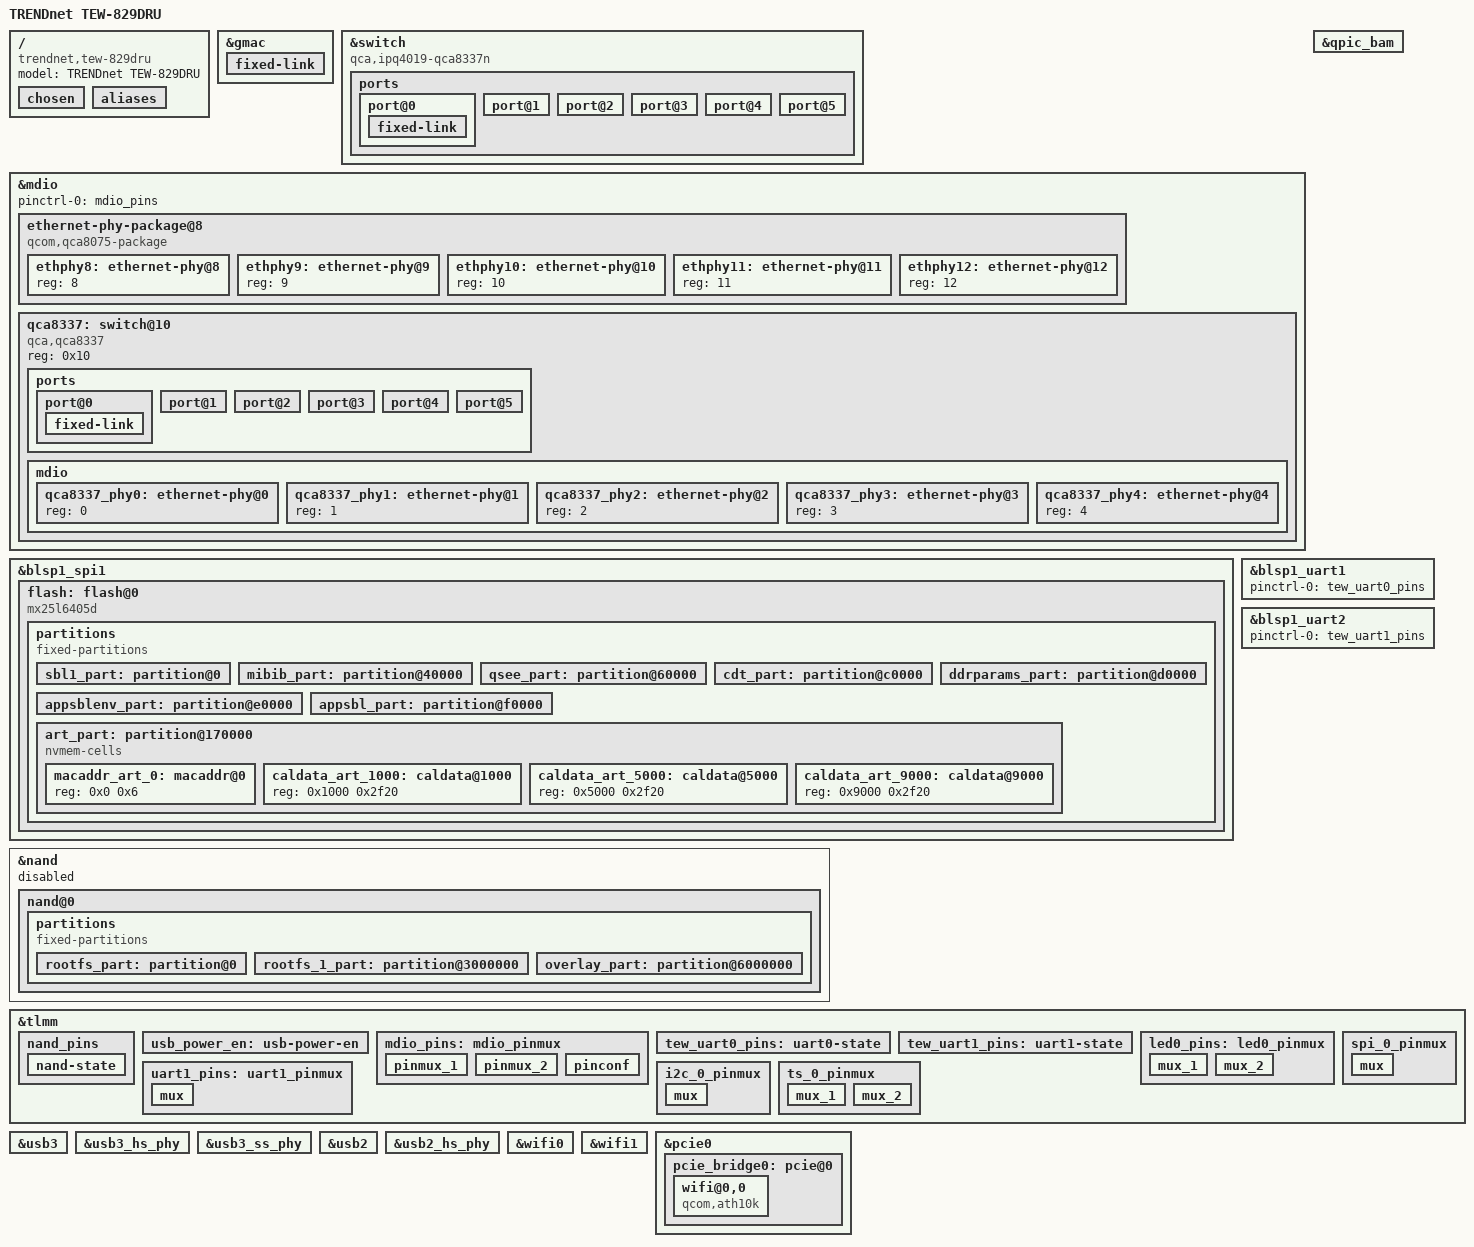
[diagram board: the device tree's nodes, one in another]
// SPDX-License-Identifier: GPL-2.0
// Copyright (c) 2018, The Linux Foundation. All rights reserved.
// Copyright (c) 2026, Your Name <your@email.com>

/*
 *		What is working?
 *
 *			- CPU
 *			- RAM
 *			- 8MB Flash (Macronix MX25L6433F SPI NOR 8MB // dual bootloader, ART, etc.)
 *			- UART
 *			- USB
  *			- wifi (QCA9984, QCA4019)
 *
 *		What is NOT working?
 *
 *			- 128MB nand (Micron MT29F1G08ABADA NAND 128MB // 2x kernel, 2x rootfs, 1x rootfs_data)
 *			- switches (QCA8075, QCA8335)
 *
 *	WARNING: ENSURE BOARD.BIN AND CALDATA IS NOT COMMITTED TO GIT REPOSITORY (INTELLECTUAL PROPERTY CONCERNS)
 *
 */

#include "qcom-ipq4019-ap.dk04.1.dtsi"

/ {

	model = "TRENDnet TEW-829DRU";
	compatible = "trendnet,tew-829dru", "qcom,ipq4019-dk04.1-c1", "qcom,ipq4019";
	
	chosen {
		bootargs = "console=ttyMSM0,115200n8 rootfstype=squashfs,jffs2 iommu.passthrough=1";
	};
	
	aliases {
		mtd0 = &sbl1_part;
		mtd1 = &mibib_part;
		mtd2 = &qsee_part;
		mtd3 = &cdt_part;
		mtd4 = &ddrparams_part;
		mtd5 = &appsblenv_part;
		mtd6 = &appsbl_part;
		mtd7 = &art_part;
		mtd8 = &rootfs_part;
		mtd9 = &rootfs_1_part;
		mtd10 = &overlay_part;
	};
}; /* end of root block */

/* EDMA — the CPU-facing ethernet, both switches connect here */
&gmac {
    status = "okay";
    phy-mode = "internal";
	/* dual-GMAC: RRD port-id 5 = GMAC1 = QCA8337 switch */
    qcom,gmac1-port = <5>;
    fixed-link {
        speed = <1000>;
        full-duplex;
        pause;
    };
}; /* end of gmac */

/* TOP SWITCH: ESS built-in (QCA8075 via PSGMII) at c000000 */
/* compatible MUST be qca,ipq4019-qca8337n — this is what ran on the device */
&switch {
    status = "okay";
    compatible = "qca,ipq4019-qca8337n";

    mdio-bus = <&mdio>;
    psgmii-ethphy = <&ethphy12>;  /* reg=0x0c, the cal PHY at base+4 */

    /delete-node/ ports;

    ports {
        #address-cells = <1>;
        #size-cells = <0>;

        port@0 {
            reg = <0>;
            label = "cpu";
            ethernet = <&gmac>;
            phy-mode = "internal";
            fixed-link {
                speed = <1000>;
                full-duplex;
                pause;
                asym-pause;
            };
        };

        port@1 {
            reg = <1>;
            label = "wan1";
            phy-handle = <&ethphy8>;
            phy-mode = "psgmii";
            status = "okay";
        };

        port@2 {
            reg = <2>;
            label = "wan2";
            phy-handle = <&ethphy9>;
            phy-mode = "psgmii";
            status = "okay";
        };

        port@3 {
            reg = <3>;
            label = "lan1";
            phy-handle = <&ethphy10>;
            phy-mode = "psgmii";
            status = "okay";
        };

        port@4 {
            reg = <4>;
            label = "lan2";
            phy-handle = <&ethphy11>;
            phy-mode = "psgmii";
            status = "okay";
        };

        port@5 {
            reg = <5>;
            label = "lan3";
            phy-handle = <&ethphy12>;   /* same as psgmii-ethphy — cal PHY doubles as port@5 */
            phy-mode = "psgmii";
            status = "okay";
        };
    };
}; /* end of switch (QCA8075) */

/* MDIO bus — contains QCA8075 package AND QCA8337 bottom switch */
&mdio {
    status = "okay";
    pinctrl-0 = <&mdio_pins>;
    pinctrl-names = "default";

    /delete-node/ ethernet-phy-package@0;

    /* QCA8075: 5-port PHY package, MDIO base addr 8 */
    ethernet-phy-package@8 {
        #address-cells = <1>;
        #size-cells = <0>;
        compatible = "qcom,qca8075-package";
        reg = <8>;
        qcom,tx-drive-strength-milliwatt = <300>;

        ethphy8:  ethernet-phy@8  { reg = <8>;  };  /* WAN1 */
        ethphy9:  ethernet-phy@9  { reg = <9>;  };  /* WAN2 */
        ethphy10: ethernet-phy@10 { reg = <10>; };  /* LAN1 */
        ethphy11: ethernet-phy@11 { reg = <11>; };  /* LAN2 */
        ethphy12: ethernet-phy@12 { reg = <12>; };  /* LAN3 / psgmii cal PHY */
    };

    /* BOTTOM SWITCH: QCA8337 — side by side, own CPU port pointing to same EDMA */
    qca8337: switch@10 {
        compatible = "qca,qca8337";
        #address-cells = <1>;
        #size-cells = <0>;
        reg = <0x10>;

        ports {
            #address-cells = <1>;
            #size-cells = <0>;

            port@0 {
                reg = <0>;
                label = "cpu";
                ethernet = <&gmac>;      /* side-by-side: ALSO points to EDMA, not to swport5 */
                phy-mode = "rgmii";
                fixed-link {
                    speed = <1000>;
                    full-duplex;
                };
            };

            port@1 {
                reg = <1>;
                label = "lan4";
                phy-mode = "internal";
                phy-handle = <&qca8337_phy0>;
            };

            port@2 {
                reg = <2>;
                label = "lan5";
                phy-mode = "internal";
                phy-handle = <&qca8337_phy1>;

            };
            port@3 {
                reg = <3>;
                label = "lan6";
                phy-mode = "internal";
                phy-handle = <&qca8337_phy2>;
            };

            port@4 {
                reg = <4>;
                label = "lan7";
                phy-mode = "internal";
                phy-handle = <&qca8337_phy3>;
            };

            port@5 {
                reg = <5>;
                label = "lan8";
                phy-mode = "internal";
                phy-handle = <&qca8337_phy4>;
            };
        };

        /* QCA8337 internal MDIO bus — local PHY addresses 0-4 */
        mdio {
            #address-cells = <1>;
            #size-cells = <0>;

            qca8337_phy0: ethernet-phy@0 { reg = <0>; };
            qca8337_phy1: ethernet-phy@1 { reg = <1>; };
            qca8337_phy2: ethernet-phy@2 { reg = <2>; };
            qca8337_phy3: ethernet-phy@3 { reg = <3>; };
            qca8337_phy4: ethernet-phy@4 { reg = <4>; };
        };
    };
}; /* end of &mdio (QCA8075/QCA8337) */

/* 8MB FLASH CHIP (Macronix MX25L6433F SPI NOR 8MB) */
&blsp1_spi1 {

	status = "okay";

	pinctrl-0 = <&spi_0_pinmux>;
	pinctrl-names = "default";

	cs-gpios = <&tlmm 12 GPIO_ACTIVE_LOW>;

	flash: flash@0 {

		#address-cells = <1>;
		#size-cells = <1>;

		compatible = "mx25l6405d", "jedec,spi-nor";

		reg = <0>;
		spi-max-frequency = <24000000>;

		partitions {
			compatible = "fixed-partitions";
			#address-cells = <1>;
			#size-cells = <1>;

			sbl1_part: partition@0 {
				label = "SBL1";
				reg = <0x0 0x40000>;
				read-only;
			};

			mibib_part: partition@40000 {
				label = "MIBIB";
				reg = <0x40000 0x20000>;
				read-only;
			};

			qsee_part: partition@60000 {
				label = "QSEE";
				reg = <0x60000 0x60000>;
				read-only;
			};

			cdt_part: partition@c0000 {
				label = "CDT";
				reg = <0xc0000 0x10000>;
				read-only;
			};

			ddrparams_part: partition@d0000 {
				label = "DDRPARAMS";
				reg = <0xd0000 0x10000>;
				read-only;
			};

			appsblenv_part: partition@e0000 {
				label = "APPSBLENV";
				reg = <0xe0000 0x10000>;
			};

			appsbl_part: partition@f0000 {
				label = "APPSBL";
				reg = <0xf0000 0x80000>;
				read-only;
			};

			art_part: partition@170000 {
				label = "ART";
				reg = <0x170000 0x10000>;
				read-only;
			};
		};
	};
};
/* end of &blsp1_spi1 (Macronix MX25L6433F SPI NOR 8MB) */

/* start of &qpic_bam (for Micron MT29F1G08ABADA NAND 128MB) */
&qpic_bam {
	status = "okay";
};
/* end of &qpic_bam (Micron MT29F1G08ABADA NAND 128MB) */

/* start of &nand (Micron MT29F1G08ABADA NAND 128MB) */
&nand {
    status = "disabled";    /* DISABLED WHILE FIGURING OUT SWITCH CONFIG */
	/delete-property/ pinctrl-0;
	/delete-property/ pinctrl-names;

    /* REMOVED PINCTRL - NO CONFLICT PLS */

    nand@0 {
        reg = <0>;

        nand-ecc-strength = <4>;
        nand-ecc-step-size = <512>;
        nand-bus-width = <8>;

        partitions {
            compatible = "fixed-partitions";
            #address-cells = <1>;
            #size-cells = <1>;

            rootfs_part: partition@0 {
                label = "rootfs";
                reg = <0x00000000 0x03000000>; /* 48MB */
            };

            rootfs_1_part: partition@3000000 {
                label = "rootfs_1";
                reg = <0x03000000 0x03000000>; /* 48MB */
            };

            overlay_part: partition@6000000 {
                label = "overlay";
                reg = <0x06000000 0x02000000>; /* 32MB */
            };
        };
    };
};
/* end of &nand (Micron MT29F1G08ABADA NAND 128MB) */




&blsp1_uart1 {
	status = "okay";
	pinctrl-0 = <&tew_uart0_pins>;
	pinctrl-names = "default";
};

&blsp1_uart2 {
	status = "okay";
	pinctrl-0 = <&tew_uart1_pins>;
	pinctrl-names = "default";
};   




&tlmm {

	nand_pins {
		nand-state {
			pins = "gpio53", "gpio55", "gpio56", "gpio57", "gpio58",
				   "gpio59", "gpio60", "gpio62", "gpio63", "gpio64",
				   "gpio65", "gpio66", "gpio67", "gpio68", "gpio69";
			function = "qpic";
			bias-disable;
		};
	};

	/* Add this GPIO Hog for USB Power */
	usb_power_en: usb-power-en {
		gpio-hog;
		gpios = <48 GPIO_ACTIVE_HIGH>;
		output-high;
		line-name = "usb-power-enable";
	};
	

    mdio_pins: mdio_pinmux {
        pinmux_1 {
            pins = "gpio53";
            function = "mdio";
        };
        pinmux_2 {
            pins = "gpio52";
            function = "mdc";
        };
        pinconf {
            pins = "gpio52", "gpio53";
            bias-pull-up;
        };
    };

	/* pinmux / gpios */
	
	/* Using Stock Router Pinout for UART0 (Console) */
	tew_uart0_pins: uart0-state {
		pins = "gpio16", "gpio17"; 
		function = "blsp_uart0";
		bias-disable;
	};

	/* Using Stock Router Pinout for UART1 (2 pins, not 4) */
	tew_uart1_pins: uart1-state {
		pins = "gpio8", "gpio9"; 
		function = "blsp_uart1";
		bias-disable;
	};

	led0_pins: led0_pinmux {
		linux,phandle = <0x52>;
		phandle = <0x52>;

		mux_1 {
			pins = "gpio36";
			function = "led0";
			bias-pull-down;
		};

		mux_2 {
			pins = "gpio40";
			function = "led4";
			bias-pull-down;
		};
	};

	uart1_pins: uart1_pinmux {
		linux,phandle = <0x56>;
		phandle = <0x56>;

		mux {
			pins = "gpio8\0gpio9\0gpio10\0gpio11";
			function = "blsp_uart1";
			bias-disable;
		};
	};

	spi_0_pinmux: spi_0_pinmux {
		linux,phandle = <0x4a>;
		phandle = <0x4a>;

		mux {
			pins = "gpio12\0gpio13\0gpio14\0gpio15";
			function = "blsp_spi0";
			bias-disable;
		};
	};

	i2c_0_pinmux: i2c_0_pinmux {
		linux,phandle = <0x4f>;
		phandle = <0x4f>;

		mux {
			pins = "gpio20\0gpio21";
			function = "blsp_i2c0";
			bias-disable;
		};
	};

	ts_0_pinmux: ts_0_pinmux {

		mux_1 {
			pins = "gpio34";
			output-high;
		};

		mux_2 {
			pins = "gpio35";
			input-enable;
			bias-pull-up;
		};
	};
	/* end of pinmux/gpios */
	
};
/* end of &tlmm */




&usb3 {
	status = "okay";
	dr_mode = "host";
	phys = <&usb3_hs_phy>, <&usb3_ss_phy>;
	phy-names = "usb2-phy", "usb3-phy";
	/* vbus-supply removed because GPIO 48 hog handles power enable */
};

&usb3_hs_phy {
	status = "okay";
};

&usb3_ss_phy {
	status = "okay";
};

&usb2 {
	status = "okay";
};

&usb2_hs_phy {
	status = "okay";
};






/* QCA4019 2GHZ */
&wifi0 {
	status = "okay";
	qcom,ath10k-calibration-variant = "TEW-829DRU-2G";
	nvmem-cells = <&caldata_art_1000>;
	nvmem-cell-names = "pre-calibration";
};

/* QCA4019 5GHZ */
&wifi1 {
	status = "okay";
	qcom,ath10k-calibration-variant = "TEW-829DRU-5G";
	nvmem-cells = <&caldata_art_5000>;
	nvmem-cell-names = "pre-calibration";
};

/* QCA9984 5GHZ */
&pcie0 {
	status = "okay";

	pcie_bridge0: pcie@0 {
		device_type = "pci";
		reg = <0x0 0x0 0x0 0x0 0x0>;
		bus-range = <0x01 0xff>;
		#address-cells = <3>;
		#size-cells = <2>;
		ranges;

		wifi@0,0 {
			compatible = "qcom,ath10k";
			reg = <0x00010000 0 0 0 0>;
			nvmem-cells = <&caldata_art_9000>;
			nvmem-cell-names = "pre-calibration";
		};
	};
};

/* ART data / caldata for wifi */
&art_part {
	compatible = "nvmem-cells";
	#address-cells = <1>;
	#size-cells = <1>;

	macaddr_art_0: macaddr@0 {
		reg = <0x0 0x6>;
	};

	/* QCA4019 2.4GHz - AHB radio wifi0 */
	caldata_art_1000: caldata@1000 {
		reg = <0x1000 0x2f20>;
	};

	/* QCA4019 5GHz - AHB radio wifi1 */
	caldata_art_5000: caldata@5000 {
		reg = <0x5000 0x2f20>;
	};

	/* QCA9984 5GHz - PCIe radio */
	caldata_art_9000: caldata@9000 {
		reg = <0x9000 0x2f20>;
	};
};



/*

 NAND TODO:
	- FIX NAND - fucking nand is impossible, memory address conflicts with qcom-ipq4019.dtsi
	- DO NOT MIX SPI/NAND PARTITIONS!
	- NAND IS DIFFERENT GPIOS, GPIO53 IS IN USE - FIND CORRECT NAND GPIO

 LED TODO:
	- Probe GPIOs
	- Add DTS config for LEDs

*/






























